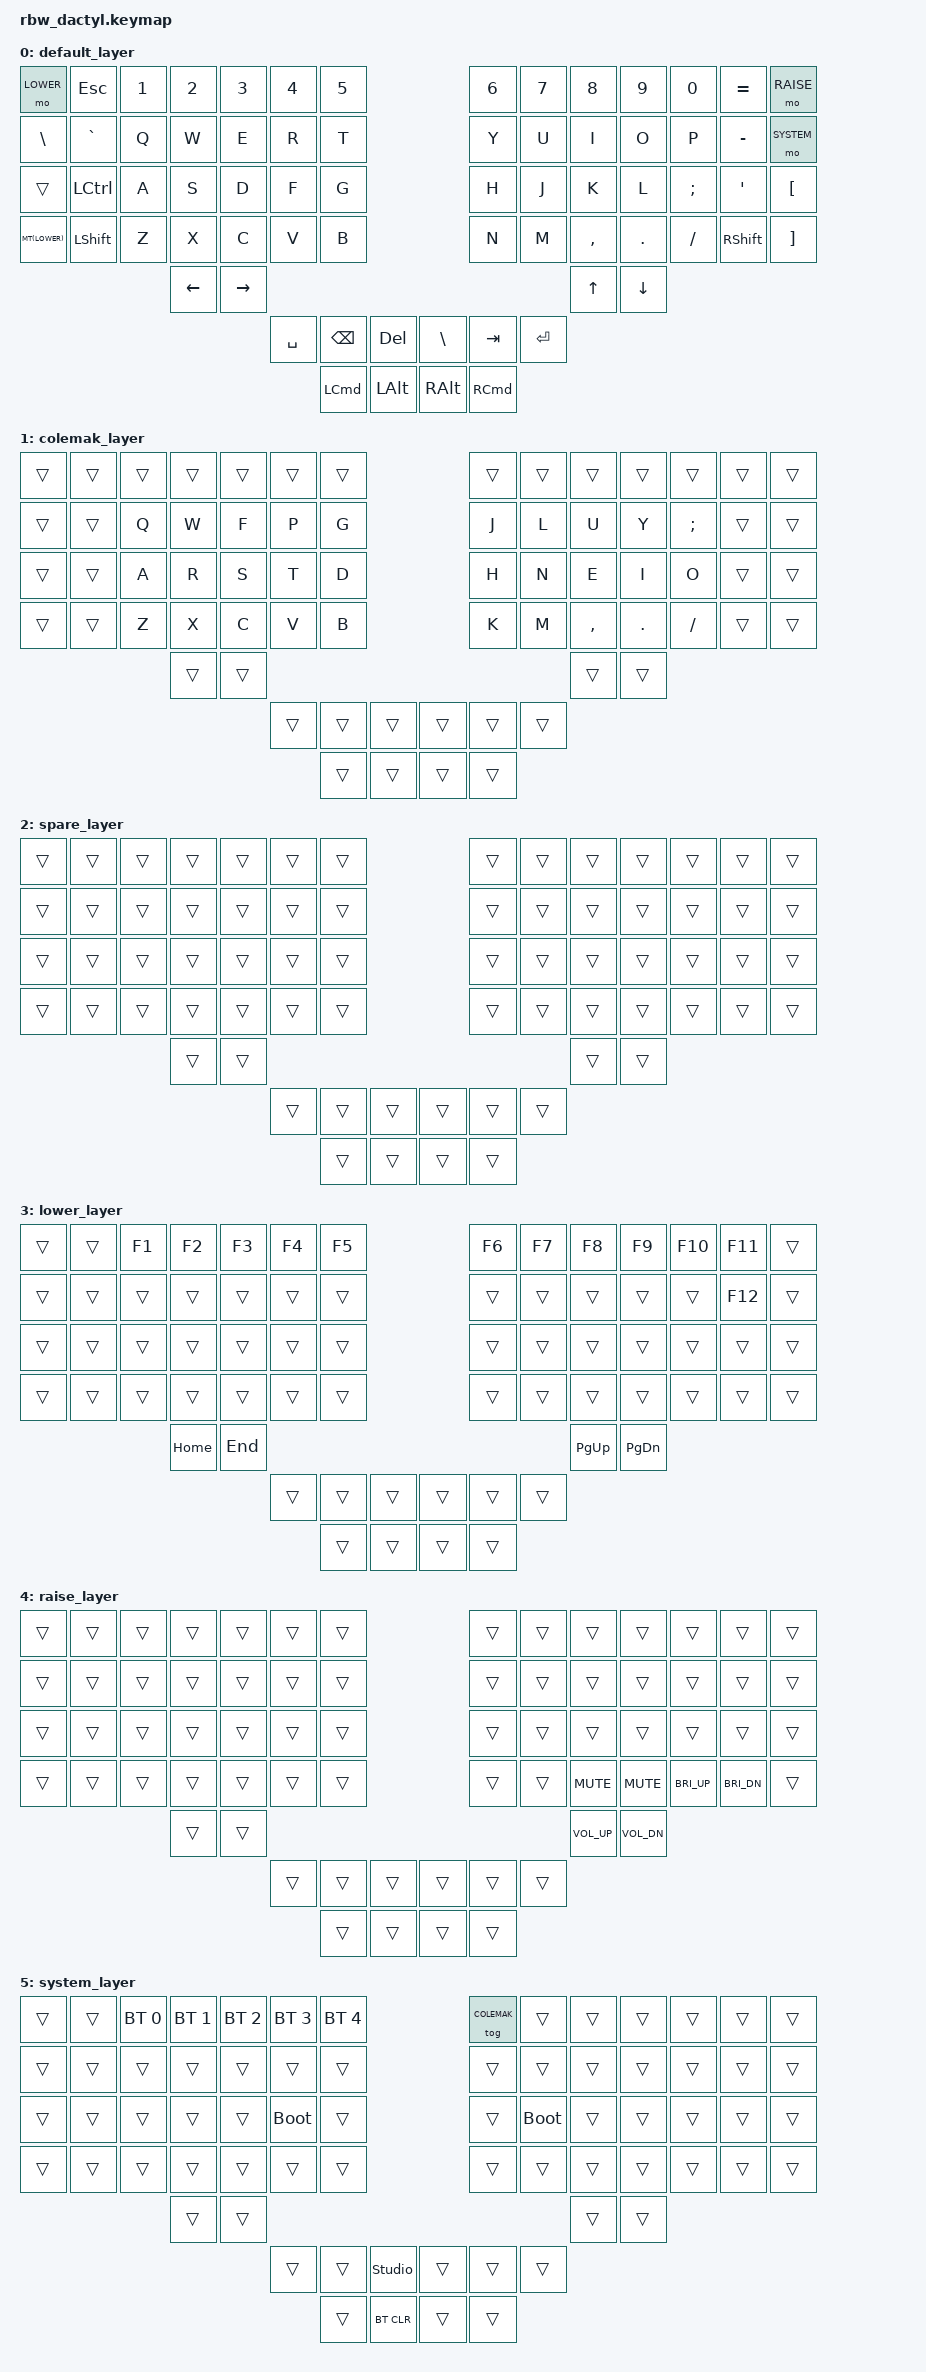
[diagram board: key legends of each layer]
#include <behaviors.dtsi>
#include <dt-bindings/zmk/keys.h>
#include <dt-bindings/zmk/bt.h>

#define DEFAULT 0
#define COLEMAK 1
#define SPARE   2
#define LOWER   3
#define RAISE   4
#define SYSTEM  5

#define MT(layer) &mo_tog layer layer

/ {
    behaviors {
        mo_tog: behavior_mo_tog {
            compatible = "zmk,behavior-hold-tap";
            #binding-cells = <2>;
            flavor = "hold-preferred";
            tapping-term-ms = <200>;
            bindings = <&mo>, <&tog>;
        };
    };

    keymap {
        compatible = "zmk,keymap";

        default_layer {
            bindings = <
    &mo LOWER   &kp ESC     &kp N1      &kp N2      &kp N3      &kp N4      &kp N5                                  &kp N6      &kp N7      &kp N8      &kp N9      &kp N0      &kp EQUAL   &mo RAISE
    &kp BSLH    &kp GRAVE   &kp Q       &kp W       &kp E       &kp R       &kp T                                   &kp Y       &kp U       &kp I       &kp O       &kp P       &kp MINUS   &mo SYSTEM
    &trans      &kp LCTRL   &kp A       &kp S       &kp D       &kp F       &kp G                                   &kp H       &kp J       &kp K       &kp L       &kp SEMI    &kp SQT     &kp LBKT
    MT(LOWER)   &kp LSHIFT  &kp Z       &kp X       &kp C       &kp V       &kp B                                   &kp N       &kp M       &kp COMMA   &kp DOT     &kp FSLH    &kp RSHIFT  &kp RBKT
                                        &kp LEFT    &kp RIGHT                                                                               &kp UP      &kp DOWN
                                                                &kp SPACE   &kp BKSP    &kp DEL         &kp BSLH    &kp TAB     &kp ENTER
                                                                            &kp LCMD    &kp LALT        &kp RALT    &kp RCMD
            >;
        };

        colemak_layer {
            bindings = <
    &trans      &trans      &trans      &trans      &trans      &trans      &trans                                  &trans      &trans      &trans      &trans      &trans      &trans      &trans
    &trans      &trans      &kp Q       &kp W       &kp F       &kp P       &kp G                                   &kp J       &kp L       &kp U       &kp Y       &kp SEMI    &trans      &trans
    &trans      &trans      &kp A       &kp R       &kp S       &kp T       &kp D                                   &kp H       &kp N       &kp E       &kp I       &kp O       &trans      &trans
    &trans      &trans      &kp Z       &kp X       &kp C       &kp V       &kp B                                   &kp K       &kp M       &kp COMMA   &kp DOT     &kp FSLH    &trans      &trans
                                        &trans      &trans                                                                                  &trans      &trans
                                                                &trans      &trans      &trans          &trans      &trans      &trans
                                                                            &trans      &trans          &trans      &trans
            >;
        };

        spare_layer {
            bindings = <
    &trans      &trans      &trans      &trans      &trans      &trans      &trans                                  &trans      &trans      &trans      &trans      &trans      &trans      &trans
    &trans      &trans      &trans      &trans      &trans      &trans      &trans                                  &trans      &trans      &trans      &trans      &trans      &trans      &trans
    &trans      &trans      &trans      &trans      &trans      &trans      &trans                                  &trans      &trans      &trans      &trans      &trans      &trans      &trans
    &trans      &trans      &trans      &trans      &trans      &trans      &trans                                  &trans      &trans      &trans      &trans      &trans      &trans      &trans
                                        &trans      &trans                                                                                  &trans      &trans
                                                                &trans      &trans      &trans          &trans      &trans      &trans
                                                                            &trans      &trans          &trans      &trans
            >;
        };

        lower_layer {
            bindings = <
    &trans      &trans      &kp F1      &kp F2      &kp F3      &kp F4      &kp F5                                  &kp F6      &kp F7      &kp F8      &kp F9      &kp F10     &kp F11     &trans
    &trans      &trans      &trans      &trans      &trans      &trans      &trans                                  &trans      &trans      &trans      &trans      &trans      &kp F12     &trans
    &trans      &trans      &trans      &trans      &trans      &trans      &trans                                  &trans      &trans      &trans      &trans      &trans      &trans      &trans
    &trans      &trans      &trans      &trans      &trans      &trans      &trans                                  &trans      &trans      &trans      &trans      &trans      &trans      &trans
                                        &kp HOME    &kp END                                                                                 &kp PG_UP   &kp PG_DN
                                                                &trans      &trans      &trans          &trans      &trans      &trans
                                                                            &trans      &trans          &trans      &trans
            >;
        };

        raise_layer {
            bindings = <
    &trans      &trans      &trans      &trans      &trans      &trans      &trans                                  &trans      &trans      &trans      &trans      &trans      &trans      &trans
    &trans      &trans      &trans      &trans      &trans      &trans      &trans                                  &trans      &trans      &trans      &trans      &trans      &trans      &trans
    &trans      &trans      &trans      &trans      &trans      &trans      &trans                                  &trans      &trans      &trans      &trans      &trans      &trans      &trans
    &trans      &trans      &trans      &trans      &trans      &trans      &trans                                  &trans      &trans      &kp C_MUTE  &kp C_MUTE  &kp C_BRI_UP &kp C_BRI_DN &trans
                                        &trans      &trans                                                                                  &kp C_VOL_UP &kp C_VOL_DN
                                                                &trans      &trans      &trans          &trans      &trans      &trans
                                                                            &trans      &trans          &trans      &trans
            >;
        };

        system_layer {
            bindings = <
    &trans      &trans      &bt BT_SEL 0 &bt BT_SEL 1 &bt BT_SEL 2 &bt BT_SEL 3 &bt BT_SEL 4                        &tog COLEMAK &trans     &trans      &trans      &trans      &trans      &trans
    &trans      &trans      &trans      &trans      &trans      &trans      &trans                                  &trans      &trans      &trans      &trans      &trans      &trans      &trans
    &trans      &trans      &trans      &trans      &trans      &bootloader &trans                                  &trans      &bootloader &trans      &trans      &trans      &trans      &trans
    &trans      &trans      &trans      &trans      &trans      &trans      &trans                                  &trans      &trans      &trans      &trans      &trans      &trans      &trans
                                        &trans      &trans                                                                                  &trans      &trans
                                                                &trans      &trans      &studio_unlock  &trans      &trans      &trans
                                                                            &trans      &bt BT_CLR      &trans      &trans
            >;
        };

    };
};
